# RZT2H register map
Vendor: Renesas Electronics Corporation; Series: RZT; File version: 1.00.00
CPU: other r0p0, little endian, MPU, no FPU, VTOR, 4 interrupt priority bits, 624 interrupts
Registers are 32-bit, read-write, reset 0x0 unless marked. A register's access mark holds for its fields unless they carry their own. Offsets are from the block's base; [hi:lo] are bit positions; {n}, {i} and the like mark numbered series.

## HDSLS20 — HIPERFACE DSL for Safe Channel 2 Unit 0
Base 0x90202000
Same registers: HDSLS{n} {0x900C2000+0x10000*n} (n=21..29), HDSLS210 0x902A2000, HDSLS211 0x902B2000, HDSLS212 0x90302000, HDSLS213 0x90312000, HDSLS214 0x90322000, HDSLS215 0x90332000
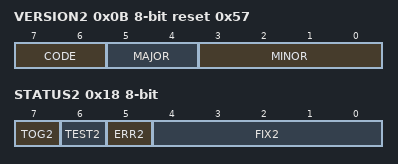
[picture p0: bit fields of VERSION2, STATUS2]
0x0B VERSION2 8-bit ro reset 0x57 — Version in Safe Channel 2 Register
  [7:6] CODE — Type of module
    1=DSL Master; other=Others (Reserved)
  [5:4] MAJOR — Major release number
  [3:0] MINOR — Minor release number
0x0F ENC2_ID 8-bit ro — Encoder ID in Safe Channel 2 Register
  [7:0] ENC2ID — Designation of the safe channel 2 channel
0x18 STATUS2 8-bit ro — Safe Channel 2 Status Register
  [7] TOG2 — Safe Channel 2 Toggle
  [6] TEST2 — Safe Channel 2 Test
  [5] ERR2 — Safe Channel 2 Position Error
    0=The last safe position received in safe channel 2 is correct; 1=The last safe position received in safe channel 2 is invalid. Suitable measures must be installed in the user application.
  [4:0] FIX2 — Safe Channel 2 Fixed Bit Pattern
0x19 VPOS24 8-bit ro — Safe Position Channel 2 Byte 4 Register
  [7:0] VPOS2 — Safe position, Channel 2, byte n
0x1A VPOS23 8-bit ro — Safe Position Channel 2 Byte 3 Register
  [7:0] VPOS2 — Safe position, Channel 2, byte n
0x1B VPOS22 8-bit ro — Safe Position Channel 2 Byte 2 Register
  [7:0] VPOS2 — Safe position, Channel 2, byte n
0x1C VPOS21 8-bit ro — Safe Position Channel 2 Byte 1 Register
  [7:0] VPOS2 — Safe position, Channel 2, byte n
0x1D VPOS20 8-bit ro — Safe Position Channel 2 Byte 0 Register
  [7:0] VPOS2 — Safe position, Channel 2, byte n
0x1E VPOSCRC2_H 8-bit ro — Safe Position CRC 2 High Byte Register
  [7:0] VPOSCRC2H — CRC of the safe position 2, bit 15 to bit 8
0x1F VPOSCRC2_L 8-bit ro — Safe Position CRC 2 Low Byte Register
  [7:0] VPOSCRC2L — CRC of the safe position 2, bit 7 to bit 0
0x3F DUMMY2 8-bit ro reset not defined — Dummy in Safe Channel 2 Register
  [7:0] DUMMY — Due to the transmission of the online-status, Online status read transactions need less time for transmission. Therefore, dummy read transactions must be inserted to avoid unwanted extra transactions.

## AFMT0 — A-format Unit 0
Base 0x90206000
Same registers: AFMT{n} {0x90206000+0x10000*n} (n=1..11), AFMT12 0x90306000, AFMT13 0x90316000, AFMT14 0x90326000, AFMT15 0x90336000
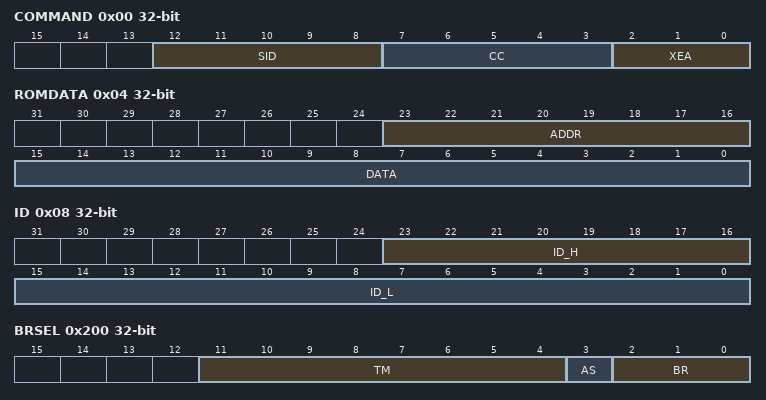
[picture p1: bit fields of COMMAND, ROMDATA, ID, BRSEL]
0x00 COMMAND wo — Command Code Encoder Address Register
  [12:8] SID — Subcommand ID
  [7:3] CC — Command code
  [2:0] XEA — Encoder address
0x00 ENC{i}RXDATA0 (i=1..8; step 0x20) ro — ENC{i} Receive Data 0 Register
  [31:0] DATA — Encoder read data
0x04 ENC{i}RXDATA1 (i=1..8; step 0x20) ro — ENC{i} Receive Data 1 Register
  [31:0] DATA — Encoder read data
0x04 ROMDATA wo — EEPROM Address and Write Data Register
  [23:16] ADDR — 8-bit EEPROM address
  [15:0] DATA — 16-bit EEPROM data
0x08 ENC{i}RXDATA2 (i=1..8; step 0x20) ro — ENC{i} Receive Data 2 Register
  [31:0] DATA — Encoder read data
0x08 ID wo — ID Code Register
  [23:16] ID_H — 24-bit ID code, high byte
  [15:0] ID_L — 24-bit ID code, low word
0x0C ENC{i}RXDATA3 (i=1..8; step 0x20) ro — ENC{i} Receive Data 3 Register
  [31:0] DATA — Encoder read data
0x10 ENC{i}RXDATA4 (i=1..8; step 0x20) ro — ENC{i} Receive Data 4 Register
  [31:0] DATA — Encoder read data
0x14 ENC{i}RXDATA5 (i=1..8; step 0x20) ro — ENC{i} Receive Data 5 Register
  [31:0] DATA — Encoder read data
0x18 ENC{i}RXDATA6 (i=1..8; step 0x20) ro — ENC{i} Receive Data 6 Register
  [31:0] DATA — Encoder read data
0x1C ENC{i}RXDATA7 (i=1..8; step 0x20) ro — ENC{i} Receive Data 7 Register
  [31:0] DATA — Encoder read data
0x100 TRGSEL wo — Trigger Select Register
  [0] EXT — Trigger select
    0=Set TRG bit in ENCnTXSEL register; 1=Trigger from ELC
0x104 TXTRG wo — Transmission Trigger Register
  [0] TRG — Command data transmission trigger generation
    0=Do nothing; 1=Transmission trigger is generated
0x200 BRSEL wo — Baud Rate Setting Register
  [11:4] TM — t2 time setting N
  [3] AS — A-Safety enable
    0=Disable; 1=Enable
  [2:0] BR — Baud rate setting
    0=2.5 Mbps; 1=4 Mbps; 2=6.67 Mbps; 3=8 Mbps; 4=16 Mbps; other=Others (Setting prohibited)

## ENCOUT — Encoder Divided-Output Module
Base 0x902C0000
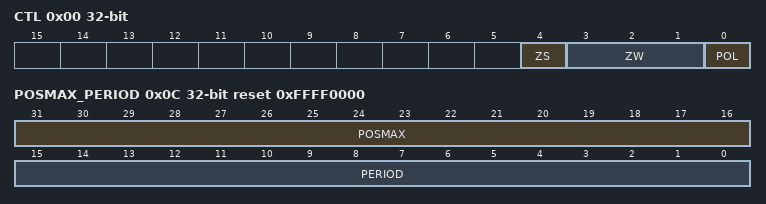
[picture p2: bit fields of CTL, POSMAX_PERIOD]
0x00 CTL — Control Register
  [4] ZS — Synchronization phase of Phase Z
    0=Phase A; 1=Phase B
  [3:1] ZW — Pulse Width of Phase Z
    0=Disable Phase Z output; 1=Pulse output when current position, POSCNT, is 0; 2=Pulse output when current position, POSCNT, is -1 and 0 (sync with Phase A) Pulse output when current position, POSCNT, is 0 and 1 (sync with Phase B); 3=Pulse output when current position, POSCNT, is -1, 0 and 1; 4=Pulse output when current position, POSCNT, is -1, 0, 1 and 2 (sync with Phase A) Pulse output when current position, POSCNT, is -2, -1, 0 and 1 (sync with Phase B); other=Others (Disable Phase Z output)
  [0] POL — Polarity of Phase B
    0=Positive phase; 1=Reversed phase
0x04 STR — Start Register
  [0] ENCE — ENCOUT Operation Start
    0=ENCOUT operation stop; 1=ENCOUT operation start
0x0C POSMAX_PERIOD reset 0xFFFF0000 — Maximum Position and Carrier Period Register
  [31:16] POSMAX — Maximum Position Setting
  [15:0] PERIOD — Carrier Period Setting
0x10 OUTCNT — Output Count Register
  [15:0] EDGCNT — Edge Count Setting
0x14 POSCNT — Position Count Register
  [15:0] POSCNT — Current Position

## PCIE_PHY
Base 0x92102000
{0x0+0x10*i} PCI_PHY_XCFGD{i} (i=0..26) reset not defined — XCFGD Setting Register {i}
  [31:0] XCFGD — Sets each bit of the PHY setting pin XCFGD.
{0x400+0x10*i} PCI_PHY_XCFGA_CMN{i} (i=0..15) — XCFGA_CMN Setting Register {i}
  [31:0] XCFGA_CMN — Sets each bit of the PHY setting pin XCFGA_CMN.
{0x500+0x10*i} PCI_PHY_XCFGA_L0{i} (i=0..5) — XCFGA_LN0 Setting Register {i}
  [31:0] XCFGA_LN0 — Sets each bit of the PHY setting pin XCFGA_LN0.
{0x560+0x10*i} PCI_PHY_XCFGA_L1{i} (i=0..5) — XCFGA_LN1 Setting Register {i}
  [31:0] XCFGA_LN1 — Sets each bit of the PHY setting pin XCFGA_LN1.
